VERSION ""

NS_ :

BS_:

BU_: BMS

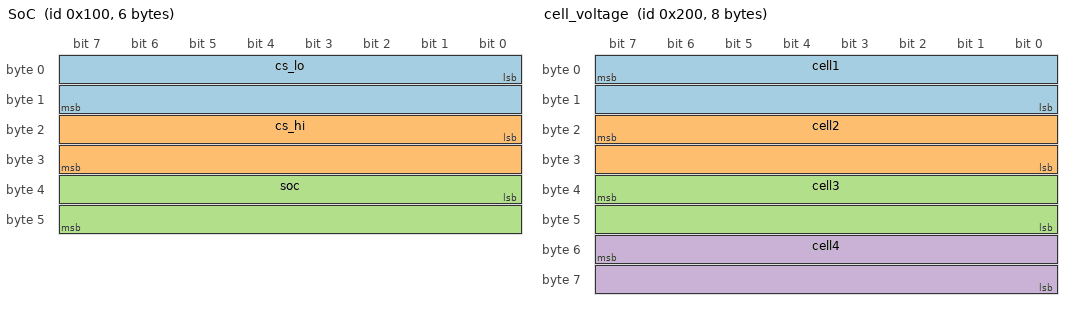
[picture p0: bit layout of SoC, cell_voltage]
BO_ 256 SoC: 6 BMS
 SG_ cs_lo : 0|16@1- (0.1,0) [0|0] "A" Vector__XXX
 SG_ cs_hi : 16|16@1- (0.1,0) [0|0] "A" Vector__XXX
 SG_ soc : 32|16@1+ (0.1,0) [0|0] "%" Vector__XXX

BO_ 512 cell_voltage: 8 BMS
 SG_ cell1 : 7|16@0+ (0.0001,0) [0|0] "V" Vector__XXX
 SG_ cell2 : 23|16@0+ (0.0001,0) [0|0] "V" Vector__XXX
 SG_ cell3 : 39|16@0+ (0.0001,0) [0|0] "V" Vector__XXX
 SG_ cell4 : 55|16@0+ (0.0001,0) [0|0] "V" Vector__XXX

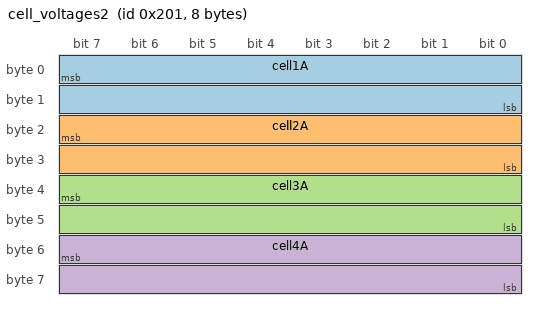
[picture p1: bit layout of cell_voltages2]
BO_ 513 cell_voltages2: 8 BMS
 SG_ cell1A : 7|16@0+ (0.0001,0) [0|0] "V" Vector__XXX
 SG_ cell2A : 23|16@0+ (0.0001,0) [0|0] "V" Vector__XXX
 SG_ cell3A : 39|16@0+ (0.0001,0) [0|0] "V" Vector__XXX
 SG_ cell4A : 55|16@0+ (0.0001,0) [0|0] "V" Vector__XXX
